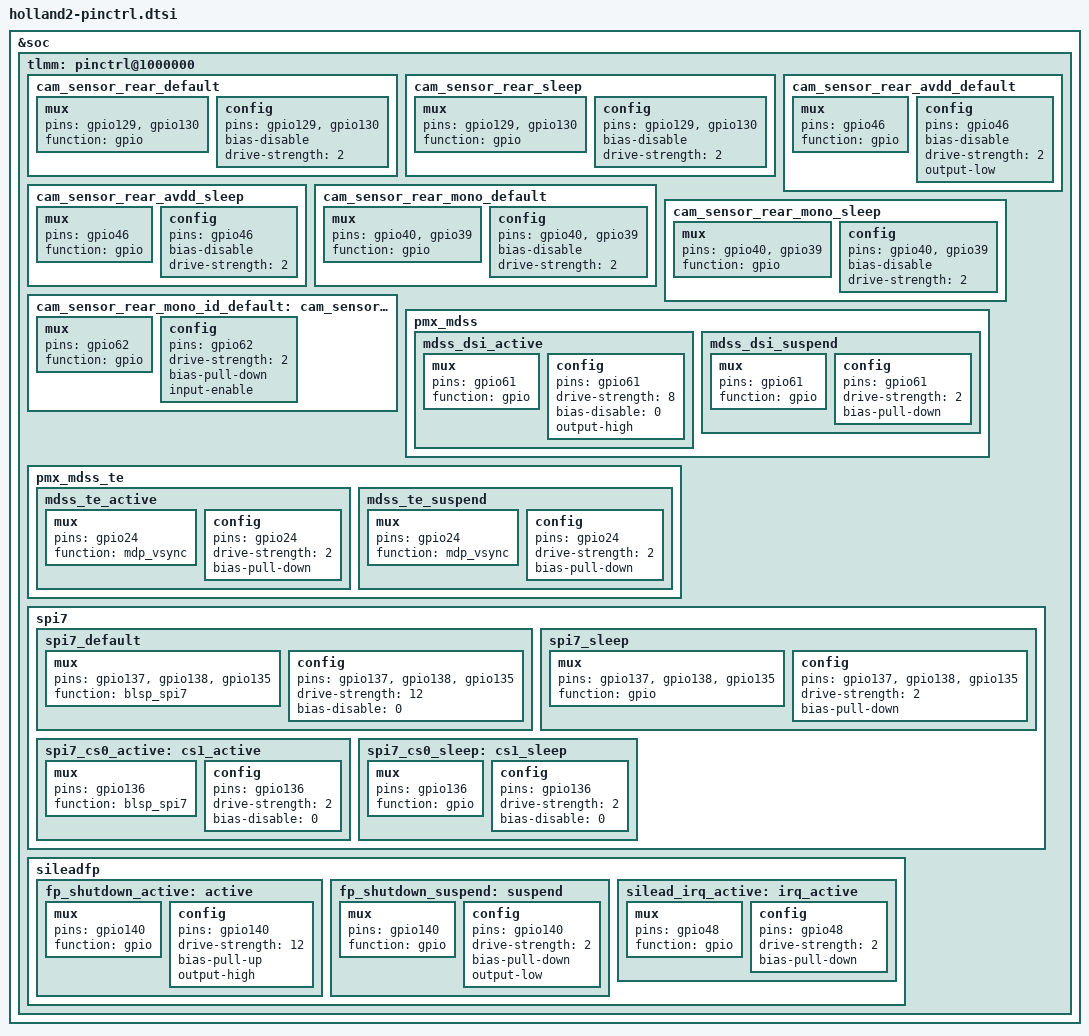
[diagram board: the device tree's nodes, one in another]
// "soc {}"

&soc {

	tlmm: pinctrl@1000000 {

		cam_sensor_rear_default: cam_sensor_rear_default {
			/* RESET, STANDBY */
			mux {
				pins = "gpio129", "gpio130";
				function = "gpio";
			};

			config {
				pins = "gpio129","gpio130";
				bias-disable; /* No PULL */
				drive-strength = <2>; /* 2 MA */
			};
		};

		cam_sensor_rear_sleep: cam_sensor_rear_sleep {
			/* RESET, STANDBY */
			mux {
				pins = "gpio129","gpio130";
				function = "gpio";
			};

			config {
				pins = "gpio129","gpio130";
				bias-disable; /* No PULL */
				drive-strength = <2>; /* 2 MA */
			};
		};

		cam_sensor_rear_avdd_default: cam_sensor_rear_avdd_default {
			/* AVDD */
			mux {
				pins = "gpio46";
				function = "gpio";
			};

			config {
				pins = "gpio46";
				bias-disable; /* No PULL */
				drive-strength = <2>; /* 2 MA */
				output-low;
			};
		};

		cam_sensor_rear_avdd_sleep: cam_sensor_rear_avdd_sleep {
			/* AVDD */
			mux {
				pins = "gpio46";
				function = "gpio";
			};

			config {
				pins = "gpio46";
				bias-disable; /* No PULL */
				drive-strength = <2>; /* 2 MA */
			};
		};

		cam_sensor_rear_mono_default: cam_sensor_rear_mono_default {
			/* RESET, STANDBY */
			mux {
				pins = "gpio40", "gpio39";
				function = "gpio";
			};

			config {
				pins = "gpio40","gpio39";
				bias-disable; /* No PULL */
				drive-strength = <2>; /* 2 MA */
			};
		};

		cam_sensor_rear_mono_sleep: cam_sensor_rear_mono_sleep {
			/* RESET, STANDBY */
			mux {
				pins = "gpio40","gpio39";
				function = "gpio";
			};

			config {
				pins = "gpio40","gpio39";
				bias-disable; /* No PULL */
				drive-strength = <2>; /* 2 MA */
			};
		};

		cam_sensor_rear_mono_id_default: cam_sensor_rear_mono_id {
			mux {
				pins = "gpio62";
				function = "gpio";
			};

			config {
				pins = "gpio62";
				drive-strength = <2>; /* 2 mA */
				bias-pull-down; /* pull down */
				input-enable;
			};
		};

		pmx_mdss: pmx_mdss {
			mdss_dsi_active: mdss_dsi_active {
				mux {
					pins = "gpio61";
					function = "gpio";
				};

				config {
					pins = "gpio61";
					drive-strength = <8>; /* 8 mA */
					bias-disable = <0>; /* no pull */
					output-high;
				};
			};

			mdss_dsi_suspend: mdss_dsi_suspend {
				mux {
					pins = "gpio61";
					function = "gpio";
				};

				config {
					pins = "gpio61";
					drive-strength = <2>; /* 2 mA */
					bias-pull-down; /* pull down */
				};
			};
		};

		pmx_mdss_te {
			mdss_te_active: mdss_te_active {
				mux {
					pins = "gpio24";
					function = "mdp_vsync";  //mdp_vsync
				};
				config {
					pins = "gpio24";
					drive-strength = <2>; /* 8 mA */
					bias-pull-down; /* pull down*/
				};
			};

			mdss_te_suspend: mdss_te_suspend {
				mux {
					pins = "gpio24";
					function = "mdp_vsync";  //mdp_vsync
				};
				config {
					pins = "gpio24";
					drive-strength = <2>; /* 2 mA */
					bias-pull-down; /* pull down */
				};
			};
		};

		spi7 {
			spi7_default: spi7_default {
				/* active state */
				mux {
					/* MOSI, MISO, CLK */
					pins = "gpio137", "gpio138", "gpio135";
					function = "blsp_spi7";
				};

				config {
					pins = "gpio137", "gpio138", "gpio135";
					drive-strength = <12>; /* 12 MA */
					bias-disable = <0>; /* No PULL */
				};
			};

			spi7_sleep: spi7_sleep {
				/* suspended state */
				mux {
					/* MOSI, MISO, CLK */
					pins = "gpio137", "gpio138", "gpio135";
					function = "gpio";
				};

				config {
					pins = "gpio137", "gpio138", "gpio135";
					drive-strength = <2>; /* 2 MA */
					bias-pull-down; /* PULL Down */
				};
			};

			spi7_cs0_active: cs1_active {
				/* CS */
				mux {
					pins = "gpio136";
					function = "blsp_spi7";
				};

				config {
					pins = "gpio136";
					drive-strength = <2>;
					bias-disable = <0>;
				};
			};

			spi7_cs0_sleep: cs1_sleep {
				/* CS */
				mux {
					pins = "gpio136";
					function = "gpio";
				};

				config {
					pins = "gpio136";
					drive-strength = <2>;
					bias-disable = <0>;
				};
			};
		};

		sileadfp {
		    fp_shutdown_active:active {
				/* shutdown */
				mux {
					pins = "gpio140";
					function = "gpio";
				};

				config {
					pins = "gpio140";
					drive-strength = <12>;
					//bias-disable = <0>;
					bias-pull-up;
					output-high;
				};
			};

			fp_shutdown_suspend:suspend {
				/* CS */
				mux {
					pins = "gpio140";
					function = "gpio";
				};

				config {
					pins = "gpio140";
					drive-strength = <2>;
					bias-pull-down;
					output-low;
				};
			};					

			silead_irq_active:irq_active {
				/* CS */
				mux {
					pins = "gpio48";
					function = "gpio";
				};

				config {
					pins = "gpio48";
					drive-strength = <2>;
					bias-pull-down;
					//input-enable;
				};
			};
		};
	};
};
